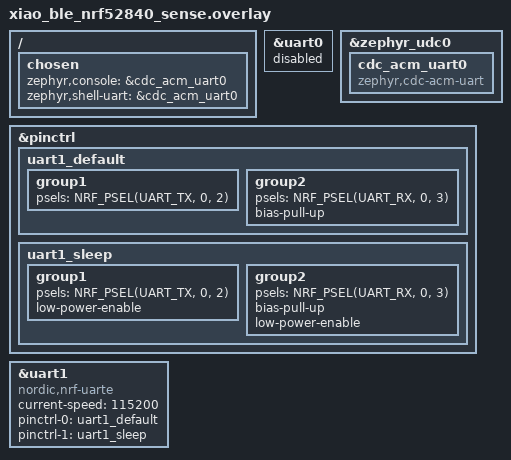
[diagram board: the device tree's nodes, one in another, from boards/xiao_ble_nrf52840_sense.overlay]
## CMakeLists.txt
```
cmake_minimum_required(VERSION 3.20.0)
find_package(Zephyr REQUIRED HINTS $ENV{ZEPHYR_BASE})
project(glazia_hub_nrf)

target_sources(app PRIVATE
    src/main.c
    src/uart_ipc.c
    src/thread_mgr.c
    src/event_relay.c
    src/led_indicator.c
)
```

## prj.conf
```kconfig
# === Networking ===
CONFIG_NETWORKING=y
CONFIG_NET_IPV6=y
CONFIG_NET_UDP=y
CONFIG_NET_SOCKETS=y
CONFIG_NET_SOCKETS_POSIX_NAMES=n
CONFIG_NET_IF_UNICAST_IPV6_ADDR_COUNT=6
CONFIG_NET_IF_MCAST_IPV6_ADDR_COUNT=8

# === OpenThread FTD (Full Thread Device — Commissioner) ===
CONFIG_NET_L2_OPENTHREAD=y
CONFIG_OPENTHREAD_FTD=y
CONFIG_OPENTHREAD_THREAD_VERSION_1_3=y
CONFIG_OPENTHREAD_BORDER_ROUTER=y
CONFIG_OPENTHREAD_COMMISSIONER=y

# === UART IPC to ESP32-S3 ===
# Async (EasyDMA) API ONLY. Do NOT also enable CONFIG_UART_INTERRUPT_DRIVEN:
# Zephyr forbids both APIs on one peripheral (CONFIG_UART_EXCLUSIVE_API_CALLBACKS),
# and on nRF UARTE it makes the per-instance binding for uart1 indeterminate, which
# silently killed RX in earlier builds. uart_ipc.c uses the async DMA path.
CONFIG_SERIAL=y
CONFIG_UART_ASYNC_API=y

# Per-instance override for uart1. The USB-CDC console enables the *global*
# CONFIG_UART_INTERRUPT_DRIVEN, which makes CONFIG_UART_1_INTERRUPT_DRIVEN default y and
# gates out CONFIG_UART_1_ASYNC (Kconfig: depends on !UART_1_INTERRUPT_DRIVEN). Without
# this, uart_callback_set() returns -ENOSYS (-88) and async RX never arms. uart1 is used
# ONLY by our async IPC code, so turning interrupt-driven off for it is safe; the console
# is a separate CDC-ACM device and keeps the global symbol.
CONFIG_UART_1_INTERRUPT_DRIVEN=n
CONFIG_UART_1_ASYNC=y

# Receiver must stay powered so asynchronously-arriving frames are never clipped/dropped.
# This defaults to y (because PM_DEVICE is off), which power-cycles the UARTE RX between
# operations -> intermittent, connect-order-dependent RX and garbled leading bytes (0xf8).
# Our RX is always-on waiting for PINGs, so keep the receiver enabled continuously.
CONFIG_UART_1_NRF_ASYNC_LOW_POWER=n

# === GPIO ===
CONFIG_GPIO=y

# === Console via USB CDC ACM (no USB-UART adapter needed) ===
# Logs appear on /dev/ttyACM* when XIAO is plugged into laptop.
# NCS 2.x: USB + MPSL coexist via Zephyr clock-control arbitration.
CONFIG_USB_DEVICE_STACK=y
CONFIG_USB_CDC_ACM=y
CONFIG_UART_LINE_CTRL=y
CONFIG_USB_DEVICE_INITIALIZE_AT_BOOT=y

# === Logging ===
CONFIG_LOG=y
CONFIG_LOG_DEFAULT_LEVEL=3
CONFIG_UART_CONSOLE=y
CONFIG_SERIAL=y

# === System ===
CONFIG_HEAP_MEM_POOL_SIZE=32768
CONFIG_MAIN_STACK_SIZE=8192
CONFIG_SYSTEM_WORKQUEUE_STACK_SIZE=4096
```

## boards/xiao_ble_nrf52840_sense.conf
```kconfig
# Board-specific Kconfig overrides for XIAO BLE nRF52840 (glazia_hub_nrf).
# BOARD_XIAO_BLE and CLOCK_CONTROL_NRF are auto-selected by the build system.
```

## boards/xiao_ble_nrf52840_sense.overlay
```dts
/* uart0 (UARTE0 @ 0x40002000) is unused — console runs over USB CDC ACM below.
 * Note: UARTE1 @ 0x40028000 is a separate instance and does NOT conflict with the
 * onboard IMU on i2c0 (0x40003000), so uart1 is free for the ESP32 IPC link. */
&uart0 {
    status = "disabled";
};

/* Route console to USB CDC ACM */
&zephyr_udc0 {
    cdc_acm_uart0: cdc_acm_uart0 {
        compatible = "zephyr,cdc-acm-uart";
    };
};

/ {
    chosen {
        zephyr,console = &cdc_acm_uart0;
        zephyr,shell-uart = &cdc_acm_uart0;
    };
};

/* Define pin control for uart1 on D0 (TX=P0.02) and D1 (RX=P0.03) */
&pinctrl {
    uart1_default: uart1_default {
        group1 {
            psels = <NRF_PSEL(UART_TX, 0, 2)>;
        };
        /* RX pull-up: line idles high when the ESP isn't driving it (unpowered/booting),
         * so no spurious start bit / garbage byte is injected regardless of connect order. */
        group2 {
            psels = <NRF_PSEL(UART_RX, 0, 3)>;
            bias-pull-up;
        };
    };
    uart1_sleep: uart1_sleep {
        group1 {
            psels = <NRF_PSEL(UART_TX, 0, 2)>;
            low-power-enable;
        };
        group2 {
            psels = <NRF_PSEL(UART_RX, 0, 3)>;
            bias-pull-up;
            low-power-enable;
        };
    };
};

/* Enable uart1 using the pins we just defined */
&uart1 {
    compatible = "nordic,nrf-uarte";
    status = "okay";
    current-speed = <115200>;
    pinctrl-0 = <&uart1_default>;
    pinctrl-1 = <&uart1_sleep>;
    pinctrl-names = "default", "sleep";
};
```

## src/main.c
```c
#include <zephyr/kernel.h>
#include <zephyr/logging/log.h>
#include <zephyr/drivers/uart.h>
#include "uart_ipc.h"
#include "thread_mgr.h"
#include "event_relay.h"
#include "led_indicator.h"

LOG_MODULE_REGISTER(glazia_hub_nrf, LOG_LEVEL_INF);

/* Block up to 3 s for picocom to assert DTR; proceeds unconditionally so production
 * boards (no host connected) are never stuck. Required because CONFIG_UART_LINE_CTRL=y
 * holds log output until DTR is asserted — without this, all boot logs are dropped. */
static void wait_for_console(void)
{
    const struct device *dev = DEVICE_DT_GET(DT_CHOSEN(zephyr_console));
    uint32_t dtr = 0;
    for (int i = 0; i < 30 && !dtr; i++) {
        uart_line_ctrl_get(dev, UART_LINE_CTRL_DTR, &dtr);
        k_msleep(100);
    }
}

static void on_ipc_cmd(uint8_t type, const uint8_t *payload, uint16_t len)
{
    switch (type) {
    case IPC_CMD_PING:
        LOG_INF("CMD_PING — sending PONG");
        uart_ipc_send(IPC_EVT_PONG, NULL, 0);
        led_hub_flash_ack_rdy();   /* blue: packet received → green: ACK sent */
        break;

    case IPC_CMD_NET_FORM:
        led_hub_flash_rx();        /* blue: packet received */
        LOG_INF("CMD_NET_FORM");
        thread_mgr_form_network();
        break;

    case IPC_CMD_NET_STATUS:
        led_hub_flash_rx();
        LOG_INF("CMD_NET_STATUS");
        thread_mgr_report_status();   /* reply with current NET_UP/NET_DOWN */
        break;

    case IPC_CMD_COMMISSION: {
        led_hub_flash_rx();
        /* payload: eui64[8] + pskd[9 null-term] + timeout_s[u16-LE] = 19 bytes */
        if (len < 19) break;
        const uint8_t *eui64   = payload;
        const char    *pskd    = (const char *)(payload + 8);
        uint16_t       timeout = (uint16_t)payload[17] | ((uint16_t)payload[18] << 8);
        thread_mgr_commission(eui64, pskd, timeout);
        break;
    }

    case IPC_CMD_SENSOR_DEL:
        led_hub_flash_rx();
        if (len >= 8) thread_mgr_remove_joiner(payload);
        break;

    case IPC_CMD_CHILD_POLL:
        led_hub_flash_rx();
        thread_mgr_report_children();   /* reply with the current child-table snapshot */
        break;

    default:
        LOG_WRN("unknown IPC cmd 0x%02x", type);
    }
}

int main(void)
{
    wait_for_console();

    /* Physical-layer wire test: 3 raw 0xFF bytes via uart_poll_out, independent of
     * any async/DMA setup. ESP32 rx_task logs "first byte from nRF on GPIO16: 0xff"
     * within ~1s if the D0(P0.02)→GPIO16 wire and GND are good. */
    {
        const struct device *raw = DEVICE_DT_GET(DT_NODELABEL(uart1));
        if (device_is_ready(raw)) {
            uart_poll_out(raw, 0xFF);
            uart_poll_out(raw, 0xFF);
            uart_poll_out(raw, 0xFF);
        }
    }

    led_hub_init();   /* 3× red blink at boot, starts LED task at DETACHED */
    LOG_INF("glazia_hub_nrf v1.0.0 starting");

    uart_ipc_init(on_ipc_cmd);
    LOG_INF("UART IPC init done — entering thread_mgr_init");
    thread_mgr_init();
    LOG_INF("thread_mgr_init done — entering event_relay_init");
    event_relay_init();

    /* Form the Thread network autonomously at boot. It's a self-contained 802.15.4 network —
     * independent of WiFi and the hub — so forming here (radio idle, uninterrupted) lets it
     * attach cleanly and fast. OpenThread then keeps it up on its own; the hub only observes
     * NET_UP. thread_mgr_form_network() is idempotent (guarded to run once). */
    LOG_INF("event_relay_init done — forming Thread network");
    thread_mgr_form_network();

    uint32_t tick = 0;
    while (1) {
        k_sleep(K_SECONDS(5));
        LOG_INF("nRF alive tick=%u", tick++);   /* nRF-side liveness only; no PONG */
    }
    return 0;
}
```

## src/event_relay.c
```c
#include <stdio.h>
#include <string.h>
#include <zephyr/kernel.h>
#include <zephyr/logging/log.h>
#include <zephyr/net/openthread.h>
#include <openthread/udp.h>
#include <openthread/ip6.h>
#include "event_relay.h"
#include "uart_ipc.h"

LOG_MODULE_REGISTER(glazia_hub_nrf_relay, LOG_LEVEL_INF);

#define SENSOR_UDP_PORT   5683   /* sensors -> hub events           */
#define DOWNLINK_UDP_PORT 5684   /* hub -> sensors control commands */

static otUdpSocket s_sock;

static int hex_nibble(char c)
{
    if (c >= '0' && c <= '9') return c - '0';
    if (c >= 'a' && c <= 'f') return c - 'a' + 10;
    if (c >= 'A' && c <= 'F') return c - 'A' + 10;
    return -1;
}

/* Parse the self-reported factory EUI64 from the JSON payload's "id" field into 8 bytes.
 * The sender's Thread mesh-local address uses a randomized ML-EID and can't be reversed to the
 * EUI64, so the sensor announces its real EUI64 in every event instead. Returns true on success. */
static bool parse_eui64_from_json(const char *json, uint8_t eui64[8])
{
    const char *p = strstr(json, "\"id\":\"");
    if (!p) return false;
    p += 6;
    for (int i = 0; i < 8; i++) {
        int hi = hex_nibble(p[i * 2]);
        int lo = hex_nibble(p[i * 2 + 1]);
        if (hi < 0 || lo < 0) return false;
        eui64[i] = (uint8_t)((hi << 4) | lo);
    }
    return true;
}

static void udp_recv_cb(void *ctx, otMessage *msg, const otMessageInfo *info)
{
    uint8_t buf[128];
    uint16_t len = otMessageGetLength(msg) - otMessageGetOffset(msg);
    if (len == 0 || len >= sizeof(buf)) return;
    otMessageRead(msg, otMessageGetOffset(msg), buf, len);
    buf[len] = '\0';

    uint8_t eui64[8];
    if (!parse_eui64_from_json((const char *)buf, eui64)) {
        LOG_WRN("event missing/invalid \"id\" EUI64 — dropping: %s", buf);
        return;
    }

    char hex[17];
    for (int i = 0; i < 8; i++) snprintf(hex + i * 2, 3, "%02x", eui64[i]);
    LOG_INF("UDP from %s: %s", hex, buf);

    ipc_send_sensor_data(eui64, (const char *)buf);
}

void event_relay_send_leave(const uint8_t eui64[8])
{
    char hex[17];
    for (int i = 0; i < 8; i++) snprintf(hex + i * 2, 3, "%02x", eui64[i]);

    char json[48];
    snprintf(json, sizeof(json), "{\"cmd\":\"leave\",\"id\":\"%s\"}", hex);

    struct openthread_context *ctx = openthread_get_default_context();
    openthread_api_mutex_lock(ctx);
    otInstance *ot = ctx->instance;

    otMessage *msg = otUdpNewMessage(ot, NULL);
    if (!msg) { openthread_api_mutex_unlock(ctx); LOG_WRN("leave: no msg buffer"); return; }
    otMessageAppend(msg, json, strlen(json));

    otMessageInfo info = {0};
    /* ff03::1 — mesh-local all-nodes multicast; only the addressed sensor acts on it. */
    info.mPeerAddr.mFields.m8[0]  = 0xff;
    info.mPeerAddr.mFields.m8[1]  = 0x03;
    info.mPeerAddr.mFields.m8[15] = 0x01;
    info.mPeerPort = DOWNLINK_UDP_PORT;

    otError err = otUdpSend(ot, &s_sock, msg, &info);
    openthread_api_mutex_unlock(ctx);
    if (err == OT_ERROR_NONE) LOG_INF("sent leave to %s", hex);
    else                      LOG_WRN("leave send failed: %d", err);
}

void event_relay_init(void)
{
    struct openthread_context *ctx = openthread_get_default_context();
    openthread_api_mutex_lock(ctx);
    otInstance *ot = ctx->instance;

    otSockAddr bind_addr = {0};
    bind_addr.mPort = SENSOR_UDP_PORT;

    otUdpOpen(ot, &s_sock, udp_recv_cb, NULL);
    otUdpBind(ot, &s_sock, &bind_addr, OT_NETIF_THREAD);

    openthread_api_mutex_unlock(ctx);
    LOG_INF("UDP event relay listening on port %d", SENSOR_UDP_PORT);
}
```

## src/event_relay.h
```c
#pragma once

#include <stdint.h>

void event_relay_init(void);

/* Multicast a "leave" command addressed (by EUI64) to a single sensor so it factory-resets and
 * drops off the Thread network. Sent when the hub deletes the sensor. */
void event_relay_send_leave(const uint8_t eui64[8]);
```

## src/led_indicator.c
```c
#include <zephyr/kernel.h>
#include <zephyr/drivers/gpio.h>
#include "led_indicator.h"

static const struct gpio_dt_spec s_red   = GPIO_DT_SPEC_GET(DT_ALIAS(led0), gpios);
static const struct gpio_dt_spec s_green = GPIO_DT_SPEC_GET(DT_ALIAS(led1), gpios);
static const struct gpio_dt_spec s_blue  = GPIO_DT_SPEC_GET(DT_ALIAS(led2), gpios);

static volatile led_hub_state_t s_state = LED_HUB_DETACHED;
static atomic_t s_flash = ATOMIC_INIT(0);

#define FLASH_JOINED      1
#define FLASH_COMM_FAILED 2
#define FLASH_RX          3   /* blue: IPC packet received */
#define FLASH_ACK_RDY     4   /* blue then green: packet received → ACK (PONG) sent */

static void all_off(void)
{
    gpio_pin_set_dt(&s_red,   0);
    gpio_pin_set_dt(&s_green, 0);
    gpio_pin_set_dt(&s_blue,  0);
}

static void do_flash(atomic_val_t type)
{
    all_off();
    switch (type) {
    case FLASH_JOINED:
        for (int i = 0; i < 2; i++) {
            gpio_pin_set_dt(&s_green, 1); k_msleep(100);
            gpio_pin_set_dt(&s_green, 0); k_msleep(100);
        }
        break;
    case FLASH_RX:
        gpio_pin_set_dt(&s_blue, 1); k_msleep(150);
        gpio_pin_set_dt(&s_blue, 0);
        break;
    case FLASH_ACK_RDY:
        gpio_pin_set_dt(&s_blue,  1); k_msleep(150);
        gpio_pin_set_dt(&s_blue,  0);
        gpio_pin_set_dt(&s_green, 1); k_msleep(150);
        gpio_pin_set_dt(&s_green, 0);
        break;
    case FLASH_COMM_FAILED:
    default:
        for (int i = 0; i < 3; i++) {
            gpio_pin_set_dt(&s_red, 1); k_msleep(100);
            gpio_pin_set_dt(&s_red, 0); k_msleep(100);
        }
        break;
    }
}

static K_THREAD_STACK_DEFINE(s_stack, 512);
static struct k_thread s_thread;

static void led_task(void *a, void *b, void *c)
{
    int tick = 0;

    while (1) {
        atomic_val_t flash = atomic_set(&s_flash, 0);
        if (flash) {
            do_flash(flash);
            tick = 0;
            continue;
        }

        switch (s_state) {
        case LED_HUB_DETACHED:
            /* Red 500 ms on/off: 10 ticks on, 10 ticks off at 50 ms/tick */
            gpio_pin_set_dt(&s_green, 0);
            gpio_pin_set_dt(&s_blue,  0);
            gpio_pin_set_dt(&s_red, (tick % 20) < 10 ? 1 : 0);
            break;
        case LED_HUB_NETWORK_UP:
            gpio_pin_set_dt(&s_red,   0);
            gpio_pin_set_dt(&s_blue,  0);
            gpio_pin_set_dt(&s_green, 1);
            break;
        case LED_HUB_COMMISSIONING:
            /* Green solid + blue 250 ms on/off: 5 ticks on, 5 ticks off */
            gpio_pin_set_dt(&s_red,   0);
            gpio_pin_set_dt(&s_green, 1);
            gpio_pin_set_dt(&s_blue, (tick % 10) < 5 ? 1 : 0);
            break;
        }

        tick++;
        k_msleep(50);
    }
}

void led_hub_init(void)
{
    if (!gpio_is_ready_dt(&s_red) ||
        !gpio_is_ready_dt(&s_green) ||
        !gpio_is_ready_dt(&s_blue)) {
        return;
    }

    gpio_pin_configure_dt(&s_red,   GPIO_OUTPUT_INACTIVE);
    gpio_pin_configure_dt(&s_green, GPIO_OUTPUT_INACTIVE);
    gpio_pin_configure_dt(&s_blue,  GPIO_OUTPUT_INACTIVE);

    /* Boot blink: 3× red = main() reached */
    for (int i = 0; i < 3; i++) {
        gpio_pin_set_dt(&s_red, 1); k_msleep(200);
        gpio_pin_set_dt(&s_red, 0); k_msleep(200);
    }

    k_thread_create(&s_thread, s_stack, K_THREAD_STACK_SIZEOF(s_stack),
                    led_task, NULL, NULL, NULL, 10, 0, K_NO_WAIT);
    k_thread_name_set(&s_thread, "led_hub");
}

void led_hub_set_state(led_hub_state_t s)  { s_state = s; }
void led_hub_flash_joined(void)            { atomic_set(&s_flash, FLASH_JOINED); }
void led_hub_flash_comm_failed(void)       { atomic_set(&s_flash, FLASH_COMM_FAILED); }
void led_hub_flash_rx(void)                { atomic_set(&s_flash, FLASH_RX); }
void led_hub_flash_ack_rdy(void)           { atomic_set(&s_flash, FLASH_ACK_RDY); }
```

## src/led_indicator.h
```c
#pragma once

typedef enum {
    LED_HUB_DETACHED,
    LED_HUB_NETWORK_UP,
    LED_HUB_COMMISSIONING,
} led_hub_state_t;

void led_hub_init(void);
void led_hub_set_state(led_hub_state_t s);
void led_hub_flash_joined(void);      /* 2× green burst */
void led_hub_flash_comm_failed(void); /* 3× red burst */
void led_hub_flash_rx(void);          /* blue: IPC packet received */
void led_hub_flash_ack_rdy(void);     /* blue → green: packet received then ACK sent */
```

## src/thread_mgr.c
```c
#include <stdio.h>
#include <string.h>
#include <zephyr/kernel.h>
#include <zephyr/logging/log.h>
#include <zephyr/net/openthread.h>
#include <openthread/thread.h>
#include <openthread/thread_ftd.h>
#include <openthread/dataset.h>
#include <openthread/dataset_ftd.h>
#include <openthread/border_router.h>
#include <openthread/commissioner.h>
#include <openthread/ip6.h>
#include "thread_mgr.h"
#include "uart_ipc.h"
#include "led_indicator.h"
#include "event_relay.h"

LOG_MODULE_REGISTER(glazia_hub_nrf_thread, LOG_LEVEL_INF);

static struct openthread_context *s_ctx;

static const char *role_str(otDeviceRole r)
{
    switch (r) {
    case OT_DEVICE_ROLE_DISABLED: return "disabled";
    case OT_DEVICE_ROLE_DETACHED: return "detached";
    case OT_DEVICE_ROLE_CHILD:    return "child";
    case OT_DEVICE_ROLE_ROUTER:   return "router";
    case OT_DEVICE_ROLE_LEADER:   return "leader";
    default:                      return "unknown";
    }
}

/* Pending joiner: an "Add Sensor" that arrived before the commissioner was ACTIVE.
 * Stashed here and flushed by commissioner_state_cb() once the petition completes. */
static uint8_t  s_pending_eui64[8];
static char     s_pending_pskd[9];
static uint16_t s_pending_timeout_s;
static bool     s_have_pending;

/* The commissioner join callback reports a *hashed* Joiner ID, not the raw factory EUI64, so it
 * cannot be sent to the server (which keys sensors by real EUI64). We keep the last EUI64 actually
 * passed to otCommissionerAddJoiner and report THAT on join/fail. Pairing is one-at-a-time on the
 * hub (server pending-sensor + s_pair_sensor_claimed gate), so a single slot is sufficient. */
static uint8_t  s_last_joiner_eui64[8];
static bool     s_have_last_joiner;

/* Add a joiner assuming the caller already holds (or must not take) the OT API mutex —
 * i.e. no locking here. Emits COMM_FAILED to the ESP on synchronous rejection. */
static void add_joiner_locked(const uint8_t eui64[8], const char *pskd, uint16_t timeout_s)
{
    otExtAddress addr;
    memcpy(addr.m8, eui64, 8);
    otError err = otCommissionerAddJoiner(s_ctx->instance, &addr, pskd,
                                          (uint32_t)timeout_s * 1000);
    if (err == OT_ERROR_NONE) {
        memcpy(s_last_joiner_eui64, eui64, 8);
        s_have_last_joiner = true;
        LOG_INF("commission: eui64=%02x%02x%02x%02x%02x%02x%02x%02x PSKd=%s timeout=%ds",
                eui64[0], eui64[1], eui64[2], eui64[3],
                eui64[4], eui64[5], eui64[6], eui64[7], pskd, timeout_s);
    } else {
        LOG_ERR("AddJoiner failed: %d", err);
        ipc_send_comm_failed(eui64);
    }
}

/* Passive per-sensor liveness. Each SED child data-polls the hub every 1 s and registers a 120 s
 * child timeout (set on the sensor). When a child stops polling, OpenThread evicts it from the
 * child table after that timeout and fires CHILD_REMOVED here; a (re)attach fires CHILD_ADDED. We
 * relay both to the ESP by the child's factory EUI64 (its 802.15.4 extended address). Runs in OT
 * callback context — read the entry and UART-send only; no OT calls, no re-lock. */
static void neighbor_cb(otNeighborTableEvent event, const otNeighborTableEntryInfo *info)
{
    if (!info) return;
    /* mExtAddress is the child's Thread MLE ext address (= factory EUI64 with the U/L bit 0x02
     * inverted). Log the raw bytes so we can confirm on HW it differs from the sensor's factory
     * EUI64 by only that bit — the ESP resolves it back to the stored EUI64 (U/L bit masked). */
    const uint8_t *m = info->mInfo.mChild.mExtAddress.m8;
    if (event == OT_NEIGHBOR_TABLE_EVENT_CHILD_REMOVED) {
        LOG_WRN("child removed (sensor lost): %02x%02x%02x%02x%02x%02x%02x%02x",
                m[0], m[1], m[2], m[3], m[4], m[5], m[6], m[7]);
        ipc_send_sensor_lost(m);
    } else if (event == OT_NEIGHBOR_TABLE_EVENT_CHILD_ADDED) {
        LOG_INF("child added (sensor online): %02x%02x%02x%02x%02x%02x%02x%02x",
                m[0], m[1], m[2], m[3], m[4], m[5], m[6], m[7]);
        ipc_send_sensor_online(m);
    }
}

/* ── On-demand child-table snapshot ─────────────────────────────────────────────
 * Reads the current Thread child table (the authoritative liveness source for the ESP watchdog)
 * into `out` as N × 8-byte MLE ext addresses and returns N. Reading the table depends only on
 * OpenThread's own child-timeout eviction (what actually removes a dead SED), not on any event
 * callback — so a present child = a live sensor. The ESP pulls this via CMD_CHILD_POLL exactly
 * when it needs to know (slow heartbeat, on toggle, after a join); we no longer push it on a
 * blind 3 s timer (that spammed the UART and raced the ESP's liveness window). */
int thread_mgr_child_snapshot(uint8_t *out, int max_children)
{
    if (!s_ctx || !out || max_children <= 0) return 0;

    int count = 0;
    openthread_api_mutex_lock(s_ctx);
    uint16_t max = otThreadGetMaxAllowedChildren(s_ctx->instance);
    for (uint16_t i = 0; i < max && count < max_children; i++) {
        otChildInfo info;
        if (otThreadGetChildInfoByIndex(s_ctx->instance, i, &info) != OT_ERROR_NONE) continue;
        memcpy(&out[count * 8], info.mExtAddress.m8, 8);
        count++;
    }
    openthread_api_mutex_unlock(s_ctx);
    return count;
}

/* Reply to CMD_CHILD_POLL: snapshot the child table and ship it to the ESP. */
void thread_mgr_report_children(void)
{
    static uint8_t list[32 * 8];
    int count = thread_mgr_child_snapshot(list, 32);
    LOG_INF("child poll (on demand): %d present", count);
    ipc_send_child_list(list, count);
}

static void state_cb(otChangedFlags flags, void *ctx)
{
    struct openthread_context *ot_ctx = (struct openthread_context *)ctx;
    openthread_api_mutex_lock(ot_ctx);
    otDeviceRole role    = otThreadGetDeviceRole(ot_ctx->instance);
    uint8_t      channel = otLinkGetChannel(ot_ctx->instance);
    uint16_t     panid   = otLinkGetPanId(ot_ctx->instance);
    openthread_api_mutex_unlock(ot_ctx);

    LOG_INF("Thread role: %s  ch=%d pan=0x%04x", role_str(role), channel, panid);

    if (role >= OT_DEVICE_ROLE_CHILD) {
        led_hub_set_state(LED_HUB_NETWORK_UP);
        ipc_send_net_up(channel, panid);
    } else {
        led_hub_set_state(LED_HUB_DETACHED);
        if (role == OT_DEVICE_ROLE_DETACHED)
            ipc_send_net_down();
    }
}

static void commissioner_state_cb(otCommissionerState state, void *ctx)
{
    static const char *const names[] = { "disabled", "petitioning", "active" };
    LOG_INF("Commissioner: %s", state < 3 ? names[state] : "unknown");
    if (state == OT_COMMISSIONER_STATE_ACTIVE) {
        led_hub_set_state(LED_HUB_COMMISSIONING);
        /* Session is up — flush any join that was deferred while petitioning.
         * This runs in OpenThread callback context, so the API mutex is already
         * effectively held: call AddJoiner directly, never re-lock (would deadlock). */
        if (s_have_pending) {
            s_have_pending = false;
            add_joiner_locked(s_pending_eui64, s_pending_pskd, s_pending_timeout_s);
        }
    } else if (state == OT_COMMISSIONER_STATE_DISABLED) {
        led_hub_set_state(LED_HUB_NETWORK_UP);
    }
}

static bool s_finalized;

static void joiner_cb(otCommissionerJoinerEvent event,
                      const otJoinerInfo *info,
                      const otExtAddress *eui64,
                      void *ctx)
{
    if (!eui64) return;

    /* Report the real factory EUI64 we added, not the callback's hashed Joiner ID (which the
     * server can't match). Fall back to the callback ID only if we somehow have no record. */
    const uint8_t *id = s_have_last_joiner ? s_last_joiner_eui64 : eui64->m8;

    if (event == OT_COMMISSIONER_JOINER_FINALIZE) {
        s_finalized = true;
        LOG_INF("sensor joined: %02x%02x%02x%02x%02x%02x%02x%02x",
                id[0], id[1], id[2], id[3], id[4], id[5], id[6], id[7]);
        led_hub_flash_joined();
        ipc_send_sensor_joined(id);
    } else if (event == OT_COMMISSIONER_JOINER_REMOVED) {
        if (!s_finalized) {
            LOG_WRN("commission failed: %02x%02x%02x%02x%02x%02x%02x%02x",
                    id[0], id[1], id[2], id[3], id[4], id[5], id[6], id[7]);
            led_hub_flash_comm_failed();
            ipc_send_comm_failed(id);
        }
        s_finalized = false;
    }
}

void thread_mgr_init(void)
{
    s_ctx = openthread_get_default_context();
    openthread_api_mutex_lock(s_ctx);
    otSetStateChangedCallback(s_ctx->instance, state_cb, s_ctx);
    otThreadRegisterNeighborTableCallback(s_ctx->instance, neighbor_cb);
    openthread_api_mutex_unlock(s_ctx);

    /* Child-table liveness is now pull-based: the ESP requests a snapshot via CMD_CHILD_POLL
     * (see thread_mgr_report_children). No blind background poller. */

    LOG_INF("thread_mgr ready");
}

void thread_mgr_form_network(void)
{
    openthread_api_mutex_lock(s_ctx);
    otInstance *ot = s_ctx->instance;

    /* Form exactly once. Thread is only ever enabled here; once enabled the role leaves
     * DISABLED for good, so a second call (e.g. a stray/legacy CMD_NET_FORM) must be a no-op —
     * re-running the enable/attach sequence disturbs MLE leader-election and stalls attach. */
    if (otThreadGetDeviceRole(ot) != OT_DEVICE_ROLE_DISABLED) {
        LOG_INF("Thread already formed (role=%s) — ignoring", role_str(otThreadGetDeviceRole(ot)));
        openthread_api_mutex_unlock(s_ctx);
        return;
    }

    /* Only create a new dataset on first boot. If one already exists in
     * non-volatile storage, reuse it so previously joined sensors stay valid. */
    otOperationalDataset existing = {0};
    bool has_dataset = (otDatasetGetActive(ot, &existing) == OT_ERROR_NONE);

    if (!has_dataset) {
        otOperationalDataset ds = {0};
        if (otDatasetCreateNewNetwork(ot, &ds) != OT_ERROR_NONE) {
            LOG_ERR("dataset create failed");
            openthread_api_mutex_unlock(s_ctx);
            return;
        }
        otDatasetSetActive(ot, &ds);

        otBorderRouterConfig br = {0};
        br.mOnMesh     = true;
        br.mSlaac      = true;
        br.mPreference = OT_ROUTE_PREFERENCE_HIGH;
        memset(br.mPrefix.mPrefix.mFields.m8, 0xfd, 1);
        br.mPrefix.mLength = 64;
        otBorderRouterAddOnMeshPrefix(ot, &br);
        otBorderRouterRegister(ot);
        LOG_INF("new Thread network created");
    } else {
        LOG_INF("restoring Thread network from flash");
    }

    otThreadSetRouterEligible(ot, true);
    otIp6SetEnabled(ot, true);
    otThreadSetEnabled(ot, true);

    /* Become leader immediately instead of waiting out OpenThread's attach-then-promote search
     * (a fresh node otherwise spends ~30 s looking for a parent to join before self-promoting).
     * This hub is the sole founder / leader / border-router / commissioner of its own private
     * network, so forming the partition directly is correct and deterministic. */
    otError lerr = otThreadBecomeLeader(ot);
    if (lerr != OT_ERROR_NONE)
        LOG_WRN("BecomeLeader returned %d — will attach normally", lerr);

    /* Do NOT start the commissioner here — petitioning during the initial attach collides with
     * MLE leader-election and stalls the network. The commissioner is started on demand by
     * thread_mgr_commission() (Add Sensor), by which point the node is already leader and the
     * petition completes immediately. */

    openthread_api_mutex_unlock(s_ctx);
    LOG_INF("Thread network %s (leader + commissioner)", has_dataset ? "restored" : "forming");
}

void thread_mgr_report_status(void)
{
    openthread_api_mutex_lock(s_ctx);
    otDeviceRole role    = otThreadGetDeviceRole(s_ctx->instance);
    uint8_t      channel = otLinkGetChannel(s_ctx->instance);
    uint16_t     panid   = otLinkGetPanId(s_ctx->instance);
    openthread_api_mutex_unlock(s_ctx);

    /* Answer an on-demand CMD_NET_STATUS query. The async state_cb only fires on role *changes*,
     * so a hub that reboots while the nRF is already up would never otherwise learn the state. */
    if (role >= OT_DEVICE_ROLE_CHILD) {
        LOG_INF("status: up (role=%s ch=%d pan=0x%04x)", role_str(role), channel, panid);
        ipc_send_net_up(channel, panid);
    } else {
        LOG_INF("status: down (role=%s)", role_str(role));
        ipc_send_net_down();
    }
}

void thread_mgr_commission(const uint8_t eui64[8], const char *pskd, uint16_t timeout_s)
{
    openthread_api_mutex_lock(s_ctx);
    otInstance *ot = s_ctx->instance;
    otCommissionerState cs = otCommissionerGetState(ot);

    /* AddJoiner is only valid once the commissioner is ACTIVE. Calling it before the petition
     * completes returns OT_ERROR_INVALID_STATE synchronously — the cause of the instant
     * "commissioning failed" on the first Add Sensor. Gate on state; defer + (re)start otherwise. */
    if (cs == OT_COMMISSIONER_STATE_ACTIVE) {
        add_joiner_locked(eui64, pskd, timeout_s);
        openthread_api_mutex_unlock(s_ctx);
        return;
    }

    /* Stash the joiner; commissioner_state_cb() flushes it when the session reaches ACTIVE. */
    memcpy(s_pending_eui64, eui64, 8);
    strncpy(s_pending_pskd, pskd, sizeof(s_pending_pskd) - 1);
    s_pending_pskd[sizeof(s_pending_pskd) - 1] = '\0';
    s_pending_timeout_s = timeout_s;
    s_have_pending = true;

    if (cs == OT_COMMISSIONER_STATE_DISABLED) {
        otError err = otCommissionerStart(ot, commissioner_state_cb, joiner_cb, NULL);
        if (err != OT_ERROR_NONE && err != OT_ERROR_ALREADY) {
            LOG_ERR("CommissionerStart failed: %d", err);
            s_have_pending = false;
            openthread_api_mutex_unlock(s_ctx);
            ipc_send_comm_failed(eui64);
            return;
        }
        LOG_INF("commissioner starting — join deferred until active");
    } else {
        LOG_INF("commissioner petitioning — join deferred until active");
    }
    openthread_api_mutex_unlock(s_ctx);
}

void thread_mgr_remove_joiner(const uint8_t eui64[8])
{
    /* Remove from the commissioning allowlist so it can't silently re-join without re-pairing. */
    openthread_api_mutex_lock(s_ctx);
    otExtAddress addr;
    memcpy(addr.m8, eui64, 8);
    otCommissionerRemoveJoiner(s_ctx->instance, &addr);
    openthread_api_mutex_unlock(s_ctx);

    /* RemoveJoiner only edits the allowlist — it can't evict an already-joined node. Send a
     * "leave" downlink so the sensor factory-resets itself off the network. */
    event_relay_send_leave(eui64);
}
```

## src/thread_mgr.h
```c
#pragma once
#include <stdint.h>

void thread_mgr_init(void);
void thread_mgr_form_network(void);
void thread_mgr_report_status(void);
void thread_mgr_commission(const uint8_t eui64[8], const char *pskd, uint16_t timeout_s);
void thread_mgr_remove_joiner(const uint8_t eui64[8]);

/* Read the current Thread child table into `out` (N × 8-byte MLE ext address); returns N. */
int  thread_mgr_child_snapshot(uint8_t *out, int max_children);
/* Snapshot the child table and send it to the ESP as IPC_EVT_CHILD_LIST (reply to CMD_CHILD_POLL). */
void thread_mgr_report_children(void);
```

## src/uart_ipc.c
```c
#include <string.h>
#include <zephyr/kernel.h>
#include <zephyr/device.h>
#include <zephyr/drivers/uart.h>
#include <zephyr/logging/log.h>
#include "uart_ipc.h"

LOG_MODULE_REGISTER(glazia_hub_nrf_ipc, LOG_LEVEL_INF);

static const struct device *s_uart;
static ipc_cmd_cb_t         s_cb;
static K_MUTEX_DEFINE(s_tx_mutex);

/* ── ISR→thread handoff: completed frames queued here, processed in rx_proc_thread ── */
struct rx_frame { uint8_t type; uint16_t len; uint8_t data[256]; };
K_MSGQ_DEFINE(s_rx_msgq, sizeof(struct rx_frame), 4, 4);
/* 8192 (not 2048): the command handlers dispatched from this thread run heavy OpenThread FTD
 * work — otDatasetCreateNewNetwork() generates the network key + PSKc via mbedTLS crypto, and
 * otCommissionerStart()/AddJoiner() are stack-hungry too. 2048 B overflowed and corrupted
 * adjacent memory (froze the LED task -> solid red). 8192 matches CONFIG_MAIN_STACK_SIZE. */
static K_THREAD_STACK_DEFINE(s_rx_stack, 12288);
static struct k_thread s_rx_thread;

/* ── Async DMA RX double-buffer ─────────────────────────────────────────────
 * nRF UARTE is EasyDMA-based; the async API is Nordic's recommended path.
 * Two ping-pong buffers keep RX continuous; the 10 ms idle timeout flushes
 * short frames (a PING is only 5 bytes and would otherwise never fill a buffer). */
#define RX_BUF_SZ     64
#define RX_TIMEOUT_US 10000
static uint8_t s_rx_buf[2][RX_BUF_SZ];
static uint8_t s_rx_next;

static void rx_proc_thread(void *a, void *b, void *c)
{
    struct rx_frame f;
    while (1) {
        if (k_msgq_get(&s_rx_msgq, &f, K_FOREVER) == 0) {
            LOG_INF("IPC rx: type=0x%02x len=%u", f.type, f.len);
            if (s_cb) s_cb(f.type, f.data, f.len);
        }
    }
}

/* ── CRC-8 (poly 0x07) ───────────────────────────────────────────────────── */
static uint8_t crc8_byte(uint8_t crc, uint8_t d)
{
    crc ^= d;
    for (int i = 0; i < 8; i++) crc = (crc & 0x80) ? (crc << 1) ^ 0x07 : (crc << 1);
    return crc;
}

static uint8_t crc8_buf(const uint8_t *d, size_t n)
{
    uint8_t c = 0;
    while (n--) c = crc8_byte(c, *d++);
    return c;
}

/* ── Frame builder: [0xA5][TYPE][LEN_LO][LEN_HI][PAYLOAD][CRC8] ─────────── */
static size_t build_frame(uint8_t type, const uint8_t *payload, uint16_t plen, uint8_t *out)
{
    out[0] = 0xA5;
    out[1] = type;
    out[2] = plen & 0xFF;
    out[3] = (plen >> 8) & 0xFF;
    if (plen && payload) memcpy(out + 4, payload, plen);
    out[4 + plen] = crc8_buf(out + 1, 3 + plen);
    return 5 + plen;
}

/* ── Parser state machine ────────────────────────────────────────────────── */
typedef enum { PS_SOF, PS_TYPE, PS_LEN0, PS_LEN1, PS_DATA, PS_CRC } pstate_t;

static struct {
    pstate_t st;
    uint8_t  type;
    uint16_t len, idx;
    uint8_t  buf[256];
    uint8_t  crc_acc;
} s_p;

static void parser_feed(uint8_t b)
{
    switch (s_p.st) {
    case PS_SOF:  if (b == 0xA5) s_p.st = PS_TYPE; break;
    case PS_TYPE: s_p.type = b; s_p.crc_acc = crc8_byte(0, b); s_p.st = PS_LEN0; break;
    case PS_LEN0: s_p.len  = b; s_p.crc_acc = crc8_byte(s_p.crc_acc, b); s_p.st = PS_LEN1; break;
    case PS_LEN1:
        s_p.len |= ((uint16_t)b << 8);
        s_p.crc_acc = crc8_byte(s_p.crc_acc, b);
        s_p.idx = 0;
        s_p.st = (s_p.len == 0) ? PS_CRC : PS_DATA;
        break;
    case PS_DATA:
        if (s_p.idx < sizeof(s_p.buf)) s_p.buf[s_p.idx] = b;
        s_p.crc_acc = crc8_byte(s_p.crc_acc, b);
        if (++s_p.idx >= s_p.len) s_p.st = PS_CRC;
        break;
    case PS_CRC:
        if (b == s_p.crc_acc) {
            struct rx_frame f = { .type = s_p.type, .len = s_p.len };
            if (s_p.len <= sizeof(f.data)) memcpy(f.data, s_p.buf, s_p.len);
            k_msgq_put(&s_rx_msgq, &f, K_NO_WAIT);
        } else {
            LOG_WRN("CRC mismatch: got 0x%02x expected 0x%02x", b, s_p.crc_acc);
        }
        s_p.st = PS_SOF;
        break;
    }
}

/* ── UART async DMA RX callback (runs in UARTE ISR context) ─────────────────
 * Keep this short: feed received bytes into the parser (which only does an
 * ISR-safe k_msgq_put on a complete frame) and hand buffers back to the DMA. */
static void uart_async_cb(const struct device *dev, struct uart_event *evt, void *ud)
{
    switch (evt->type) {
    case UART_RX_RDY:
        for (size_t i = 0; i < evt->data.rx.len; i++)
            parser_feed(evt->data.rx.buf[evt->data.rx.offset + i]);
        break;
    case UART_RX_BUF_REQUEST:
        uart_rx_buf_rsp(dev, s_rx_buf[s_rx_next], RX_BUF_SZ);
        s_rx_next ^= 1;
        break;
    case UART_RX_STOPPED:
        /* Framing/overrun/parity error (e.g. a connect-time line glitch). The driver will
         * follow with UART_RX_DISABLED, where we re-arm — just note it, never leave RX dead. */
        LOG_WRN("RX stopped, reason=%d", evt->data.rx_stop.reason);
        break;
    case UART_RX_DISABLED: {        /* re-arm so RX can never stay dead after an error */
        int err;
        do {
            err = uart_rx_enable(dev, s_rx_buf[0], RX_BUF_SZ, RX_TIMEOUT_US);
        } while (err == -EBUSY);
        s_rx_next = 1;
        break;
    }
    default:
        break;
    }
}

/* ── Public API ──────────────────────────────────────────────────────────── */
void uart_ipc_init(ipc_cmd_cb_t cb)
{
    s_cb   = cb;
    s_uart = DEVICE_DT_GET(DT_NODELABEL(uart1));
    if (!device_is_ready(s_uart)) {
        LOG_ERR("UART1 not ready");
        return;
    }

    int err = uart_callback_set(s_uart, uart_async_cb, NULL);
    if (err) { LOG_ERR("uart_callback_set failed: %d", err); return; }

    err = uart_rx_enable(s_uart, s_rx_buf[0], RX_BUF_SZ, RX_TIMEOUT_US);
    if (err) { LOG_ERR("uart_rx_enable failed: %d", err); return; }
    s_rx_next = 1;

    k_thread_create(&s_rx_thread, s_rx_stack, K_THREAD_STACK_SIZEOF(s_rx_stack),
                    rx_proc_thread, NULL, NULL, NULL, 5, 0, K_NO_WAIT);
    k_thread_name_set(&s_rx_thread, "ipc_rx");
    LOG_INF("IPC UART1 ready (async DMA, TX=D0/P0.02 RX=D1/P0.03)");
}

void uart_ipc_send(uint8_t type, const uint8_t *payload, uint16_t plen)
{
    uint8_t frame[5 + 256];
    size_t flen = build_frame(type, payload, plen > 256 ? 256 : plen, frame);
    k_mutex_lock(&s_tx_mutex, K_FOREVER);
    for (size_t i = 0; i < flen; i++) uart_poll_out(s_uart, frame[i]);
    k_mutex_unlock(&s_tx_mutex);
}

void ipc_send_net_up(uint8_t channel, uint16_t panid)
{
    uint8_t p[3] = { channel, panid & 0xFF, (panid >> 8) & 0xFF };
    uart_ipc_send(IPC_EVT_NET_UP, p, sizeof(p));
}

void ipc_send_net_down(void) { uart_ipc_send(IPC_EVT_NET_DOWN, NULL, 0); }

void ipc_send_sensor_joined(const uint8_t eui64[8])
{
    uart_ipc_send(IPC_EVT_SENSOR_JOINED, eui64, 8);
}

void ipc_send_sensor_data(const uint8_t eui64[8], const char *json)
{
    uint8_t buf[8 + 128];
    memcpy(buf, eui64, 8);
    size_t jlen = strlen(json);
    if (jlen > 127) jlen = 127;
    memcpy(buf + 8, json, jlen);
    buf[8 + jlen] = '\0';
    uart_ipc_send(IPC_EVT_SENSOR_DATA, buf, 8 + jlen + 1);
}

void ipc_send_comm_failed(const uint8_t eui64[8])
{
    uart_ipc_send(IPC_EVT_COMM_FAILED, eui64, 8);
}

void ipc_send_sensor_lost(const uint8_t eui64[8])
{
    uart_ipc_send(IPC_EVT_SENSOR_LOST, eui64, 8);
}

void ipc_send_sensor_online(const uint8_t eui64[8])
{
    uart_ipc_send(IPC_EVT_SENSOR_ONLINE, eui64, 8);
}

void ipc_send_child_list(const uint8_t *extaddrs, int n_children)
{
    if (n_children < 0) n_children = 0;
    if (n_children > 32) n_children = 32;   /* 32*8 = 256 payload cap */
    uart_ipc_send(IPC_EVT_CHILD_LIST, extaddrs, (uint16_t)(n_children * 8));
}
```

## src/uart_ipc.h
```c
#pragma once
#include <stdint.h>
#include <stddef.h>

/* Frame: [0xA5][TYPE][LEN_LO][LEN_HI][PAYLOAD...][CRC8-poly0x07]
 * Binary-compatible with ESP32-S3 nrf_ipc.c (same byte values, same CRC). */

/* Commands received from ESP32-S3 */
#define IPC_CMD_PING        0x00  /* no payload — reply with IPC_EVT_PONG */
#define IPC_CMD_NET_FORM    0x01
#define IPC_CMD_NET_STATUS  0x02
#define IPC_CMD_COMMISSION  0x03  /* eui64[8] + pskd[9 null-term] + timeout_s[u16-LE] */
#define IPC_CMD_SENSOR_DEL  0x04  /* eui64[8] */
#define IPC_CMD_CHILD_POLL  0x05  /* no payload — reply with IPC_EVT_CHILD_LIST (current child table) */

/* Events sent to ESP32-S3 */
#define IPC_EVT_PONG           0x80  /* no payload — reply to IPC_CMD_PING */
#define IPC_EVT_NET_UP         0x81  /* channel[1] + panid[2-LE] */
#define IPC_EVT_NET_DOWN       0x82
#define IPC_EVT_SENSOR_JOINED  0x83  /* eui64[8] */
#define IPC_EVT_SENSOR_DATA    0x84  /* eui64[8] + JSON string (null-term) */
#define IPC_EVT_COMM_FAILED    0x85  /* eui64[8] */
#define IPC_EVT_SENSOR_LOST    0x86  /* eui64[8] — child aged out of the Thread child table */
#define IPC_EVT_SENSOR_ONLINE  0x87  /* eui64[8] — child (re)attached to the Thread child table */
#define IPC_EVT_CHILD_LIST     0x88  /* N × extaddr[8] — snapshot of the current Thread child table */

typedef void (*ipc_cmd_cb_t)(uint8_t type, const uint8_t *payload, uint16_t len);

void uart_ipc_init(ipc_cmd_cb_t cb);
void uart_ipc_send(uint8_t type, const uint8_t *payload, uint16_t len);

void ipc_send_net_up(uint8_t channel, uint16_t panid);
void ipc_send_net_down(void);
void ipc_send_sensor_joined(const uint8_t eui64[8]);
void ipc_send_sensor_data(const uint8_t eui64[8], const char *json);
void ipc_send_comm_failed(const uint8_t eui64[8]);
void ipc_send_sensor_lost(const uint8_t eui64[8]);
void ipc_send_sensor_online(const uint8_t eui64[8]);
void ipc_send_child_list(const uint8_t *extaddrs, int n_children);
```
